# STM32U5G7xx register map
File version: 1.0
Registers are 32-bit, read-write, reset 0x0 unless marked. A register's access mark holds for its fields unless they carry their own. Offsets are from the block's base; [hi:lo] are bit positions; {n}, {i} and the like mark numbered series.

## DCMI
Base 0x4202C000
Same registers: DCMI_S 0x5202C000
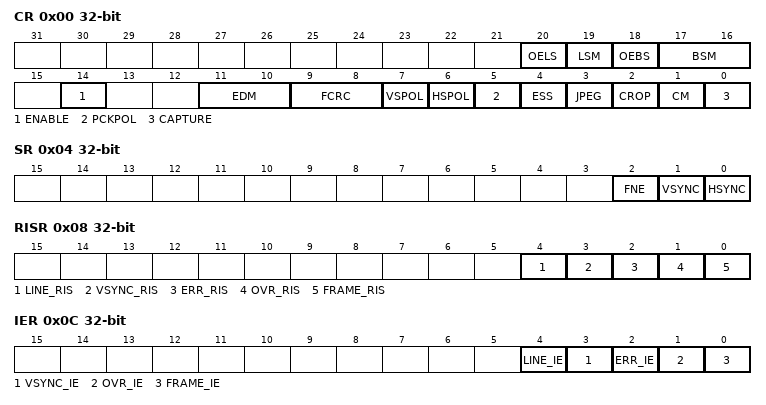
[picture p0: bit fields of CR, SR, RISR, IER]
0x00 CR — DCMI control register 1
  [20] OELS
  [19] LSM
  [18] OEBS
  [17:16] BSM
  [14] ENABLE
  [11:10] EDM — DCMI Extended data mode EDM[1:0]
  [9:8] FCRC — DCMI Frame capture rate control FCRC[1:0]
  [7] VSPOL
  [6] HSPOL
  [5] PCKPOL
  [4] ESS
  [3] JPEG
  [2] CROP
  [1] CM
  [0] CAPTURE
0x04 SR — DCMI status register
  [2] FNE, [1] VSYNC, [0] HSYNC
0x08 RISR — DCMI raw interrupt status register
  [4] LINE_RIS, [3] VSYNC_RIS, [2] ERR_RIS, [1] OVR_RIS, [0] FRAME_RIS
0x0C IER — DCMI interrupt enable register
  [4] LINE_IE, [3] VSYNC_IE, [2] ERR_IE, [1] OVR_IE, [0] FRAME_IE
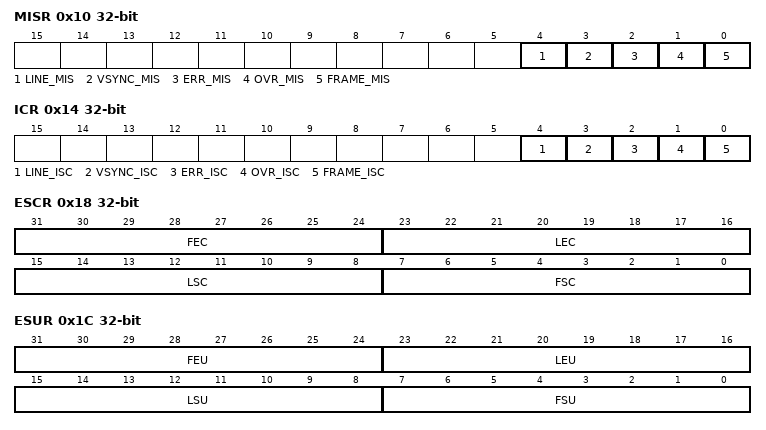
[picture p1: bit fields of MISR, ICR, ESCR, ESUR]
0x10 MISR — DCMI masked interrupt status register
  [4] LINE_MIS, [3] VSYNC_MIS, [2] ERR_MIS, [1] OVR_MIS, [0] FRAME_MIS
0x14 ICR — DCMI interrupt clear register
  [4] LINE_ISC, [3] VSYNC_ISC, [2] ERR_ISC, [1] OVR_ISC, [0] FRAME_ISC
0x18 ESCR — DCMI embedded synchronization code register
  [31:24] FEC, [23:16] LEC, [15:8] LSC, [7:0] FSC
0x1C ESUR — DCMI embedded synchronization unmask register
  [31:24] FEU, [23:16] LEU, [15:8] LSU, [7:0] FSU
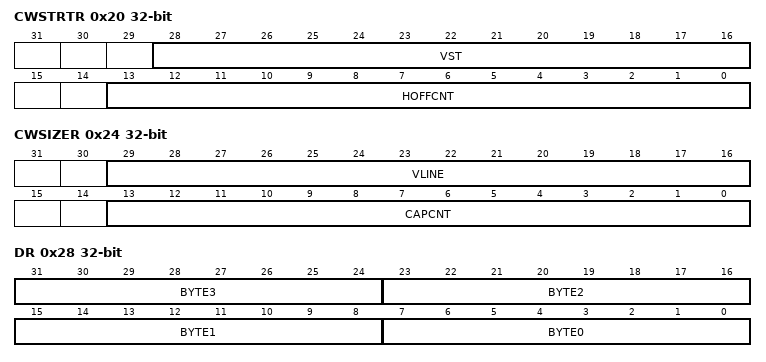
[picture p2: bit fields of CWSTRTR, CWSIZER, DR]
0x20 CWSTRTR — DCMI crop window start
  [28:16] VST, [13:0] HOFFCNT
0x24 CWSIZER — DCMI crop window size
  [29:16] VLINE, [13:0] CAPCNT
0x28 DR — DCMI data register
  [8n+7:8n] BYTE{n} (n=0..3)

## PSSI
Base 0x4202C400
Same registers: PSSI_S 0x5202C400
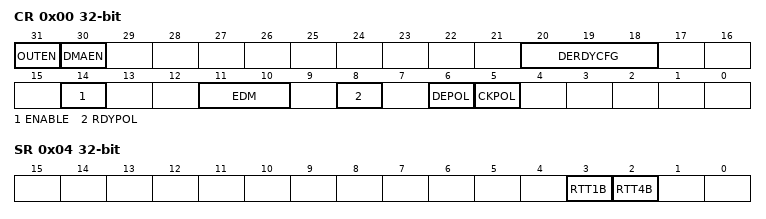
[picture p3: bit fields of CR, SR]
0x00 CR — PSSI control register
  [31] OUTEN — Data direction selection
  [30] DMAEN — DMA enable
  [20:18] DERDYCFG — Data enable and ready configuration
  [14] ENABLE — PSSI enable
  [11:10] EDM — Extended data mode
  [8] RDYPOL — Ready polarity
  [6] DEPOL — Data enable polarity
  [5] CKPOL — Parallel data clock polarity
0x04 SR — PSSI status register
  [3] RTT1B — Ready to transfer one byte
  [2] RTT4B — Ready to transfer four bytes
0x08 RIS — PSSI raw interrupt status register
  [1] OVR_RIS — Data buffer overrun/underrun raw interrupt status
0x0C IER — PSSI interrupt enable register
  [1] OVR_IE — Data buffer overrun/underrun interrupt enable
0x10 MIS — PSSI masked interrupt status register
  [1] OVR_MIS — Data buffer overrun/underrun masked interrupt status
0x14 ICR — PSSI interrupt clear register
  [1] OVR_ISC — Data buffer overrun/underrun interrupt status clear
0x28 DR — PSSI data register
  [31:0] DR — Data register

## AES — AES hardware accelerator
Base 0x420C0000
Same registers: SAES 0x420C0C00, AES_S 0x520C0000, SAES_S 0x520C0C00
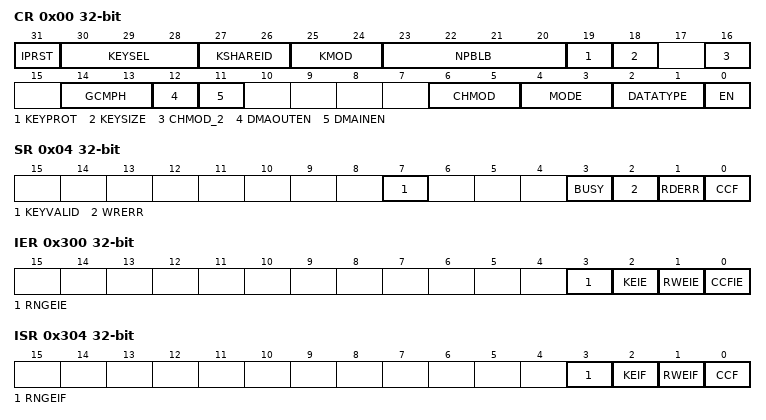
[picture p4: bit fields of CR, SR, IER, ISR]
0x00 CR — AES control register
  [31] IPRST — AES IP software reset
  [30:28] KEYSEL — Key Selection
  [27:26] KSHAREID — Key Shared ID
  [25:24] KMOD — Key mode selection
  [23:20] NPBLB — Number of padding bytes in payload last block
  [19] KEYPROT — Key protection
  [18] KEYSIZE — Key size selection
  [16] CHMOD_2 — AES Chaining Mode
  [14:13] GCMPH — GCM Phase
  [12] DMAOUTEN — Enable data output phase DMA management
  [11] DMAINEN — Enable data input phase DMA management
  [6:5] CHMOD — AES Chaining Mode
  [4:3] MODE — AES Mode Of Operation
  [2:1] DATATYPE — Data type selection
  [0] EN — AES Enable
0x04 SR — AES status register
  [7] KEYVALID — KEYVALID Flag
  [3] BUSY — Busy Flag
  [2] WRERR — Write Error Flag
  [1] RDERR — Read Error Flag
  [0] CCF — Computation Complete Flag
0x08 DINR — AES data input register
  [31:0] DINR — AES Data Input Register
0x0C DOUTR — AES data output register
  [31:0] DOUTR — AES Data Output Register
{0x10+4i} KEYR{i} (i=0..3) — AES key register {i}
  [31:0] KEYR{i} — AES Key Register {i}
{0x20+4i} IVR{i} (i=0..3) — AES initialization vector register {i}
  [31:0] IVR{i} — AES Initialization Vector Register {i}
{0x20+4i} KEYR{i} (i=4..7) — AES key register {i}
  [31:0] KEYR{i} — AES Key Register {i}
{0x40+4i} SUSP{i}R (i=0..7) — AES Suspend register {i}
  [31:0] SUSP{i}R — AES Suspend registers {i}
0x300 IER — AES Interrupt Enable Register
  [3] RNGEIE — Rng error interrupt enable
  [2] KEIE — Key error interrupt enable
  [1] RWEIE — Read or write error Interrupt Enable
  [0] CCFIE — Computation complete flag interrupt enable
0x304 ISR — AES Interrupt Status Register
  [3] RNGEIF — Rng error interrupt flag
  [2] KEIF — Key error interrupt flag
  [1] RWEIF — Read or write error Interrupt flag
  [0] CCF — Computation complete flag
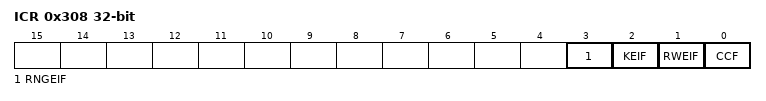
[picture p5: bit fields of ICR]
0x308 ICR — AES Interrupt Clear Register
  [3] RNGEIF — Rng error interrupt flag clear
  [2] KEIF — Key error interrupt flag clear
  [1] RWEIF — Read or write error Interrupt flag clear
  [0] CCF — Computation complete flag clear
